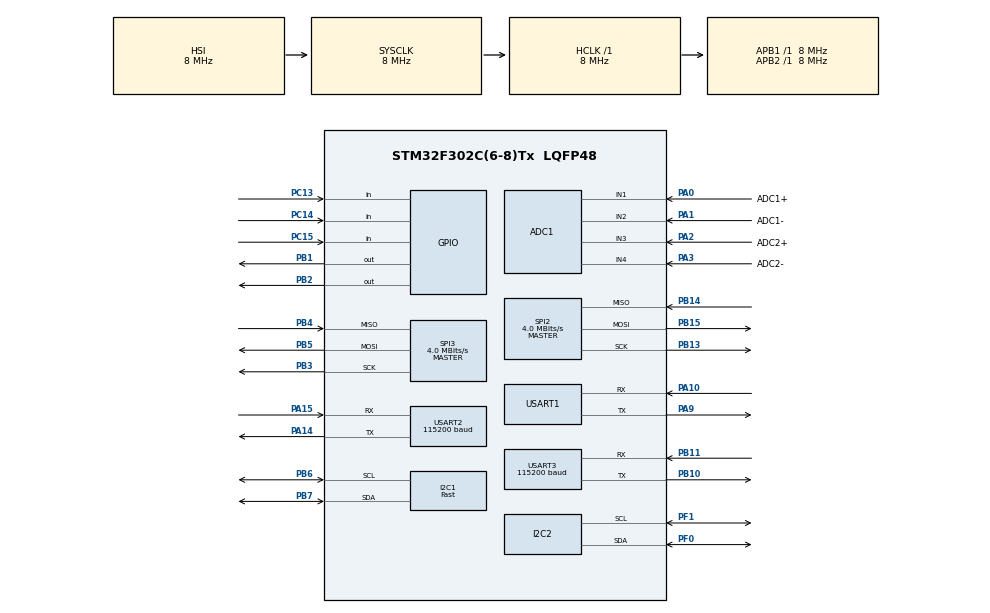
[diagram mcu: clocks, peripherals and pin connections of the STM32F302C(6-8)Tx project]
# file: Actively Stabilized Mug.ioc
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ADC1.Channel-2\#ChannelRegularConversion=ADC_CHANNEL_1
ADC1.NbrOfConversionFlag=1
ADC1.Offset-2\#ChannelRegularConversion=0
ADC1.OffsetNumber-2\#ChannelRegularConversion=ADC_OFFSET_NONE
ADC1.Rank-2\#ChannelRegularConversion=1
ADC1.SamplingTime-2\#ChannelRegularConversion=ADC_SAMPLETIME_1CYCLE_5
ADC1.SingleDiff-2\#ChannelRegularConversion=ADC_DIFFERENTIAL_ENDED
ADC1.SubFamily=STM32F302x8
ADC1.master=1
I2C1.I2C_Speed_Mode=I2C_Fast
I2C1.Timing=0x0000020B
Mcu.Family=STM32F3
Mcu.Name=STM32F302C(6-8)Tx
Mcu.Package=LQFP48
NVIC.PriorityGroup=NVIC_PRIORITYGROUP_4
PA0.GPIO_Label=ADC1+
PA0.Mode=IN1-Differential
PA0.Signal=ADC1_IN1
PA1.GPIO_Label=ADC1-
PA1.Mode=IN1-Differential
PA1.Signal=ADC1_IN2
PA10.Mode=Asynchronous
PA10.Signal=USART1_RX
PA14.Mode=Asynchronous
PA14.Signal=USART2_TX
PA15.Mode=Asynchronous
PA15.Signal=USART2_RX
PA2.GPIO_Label=ADC2+
PA2.Mode=IN3-Differential
PA2.Signal=ADC1_IN3
PA3.GPIO_Label=ADC2-
PA3.Mode=IN3-Differential
PA3.Signal=ADC1_IN4
PA9.Mode=Asynchronous
PA9.Signal=USART1_TX
PB1.GPIO_Speed=GPIO_SPEED_FREQ_HIGH
PB1.Signal=GPIO_Output
PB10.GPIO_PuPd=GPIO_PULLUP
PB10.Mode=Asynchronous
PB10.Signal=USART3_TX
PB11.GPIO_PuPd=GPIO_PULLUP
PB11.Mode=Asynchronous
PB11.Signal=USART3_RX
PB13.Mode=Full_Duplex_Master
PB13.Signal=SPI2_SCK
PB14.Mode=Full_Duplex_Master
PB14.Signal=SPI2_MISO
PB15.Mode=Full_Duplex_Master
PB15.Signal=SPI2_MOSI
PB2.Signal=GPIO_Output
PB3.Mode=Full_Duplex_Master
PB3.Signal=SPI3_SCK
PB4.Mode=Full_Duplex_Master
PB4.Signal=SPI3_MISO
PB5.Mode=Full_Duplex_Master
PB5.Signal=SPI3_MOSI
PB6.Mode=I2C
PB6.Signal=I2C1_SCL
PB7.Mode=I2C
PB7.Signal=I2C1_SDA
PC13.Signal=GPIO_Input
PC14\ -\ OSC32_IN.Signal=GPIO_Input
PC15\ -\ OSC32_OUT.Signal=GPIO_Input
PF0-OSC_IN.Mode=I2C
PF0-OSC_IN.Signal=I2C2_SDA
PF1-OSC_OUT.Mode=I2C
PF1-OSC_OUT.Signal=I2C2_SCL
ProjectManager.HeapSize=0x200
ProjectManager.StackSize=0x400
ProjectManager.TargetToolchain=STM32CubeIDE
RCC.AHBFreq_Value=8000000
RCC.APB1Freq_Value=8000000
RCC.APB1TimFreq_Value=8000000
RCC.APB2Freq_Value=8000000
RCC.CortexFreq_Value=8000000
RCC.HSE_VALUE=8000000
RCC.HSI_VALUE=8000000
RCC.LSE_VALUE=32768
RCC.PLLMUL=RCC_PLL_MUL4
RCC.SYSCLKFreq_VALUE=8000000
RCC.USBFreq_Value=16000000
SPI2.CalculateBaudRate=4.0 MBits/s
SPI2.Direction=SPI_DIRECTION_2LINES
SPI2.Mode=SPI_MODE_MASTER
SPI2.VirtualType=VM_MASTER
SPI3.CalculateBaudRate=4.0 MBits/s
SPI3.Direction=SPI_DIRECTION_2LINES
SPI3.Mode=SPI_MODE_MASTER
SPI3.VirtualType=VM_MASTER
USART1.VirtualMode-Asynchronous=VM_ASYNC
USART2.BaudRate=115200
USART2.VirtualMode-Asynchronous=VM_ASYNC
USART3.BaudRate=115200
USART3.VirtualMode-Asynchronous=VM_ASYNC
board=custom

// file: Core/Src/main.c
/* USER CODE BEGIN Header */
/**
  ******************************************************************************
  * @file           : main.c
  * @brief          : Main program body
  ******************************************************************************
  * @attention
  *
  * Copyright (c) 2022 STMicroelectronics.
  * All rights reserved.
  *
  * This software is licensed under terms that can be found in the LICENSE file
  * in the root directory of this software component.
  * If no LICENSE file comes with this software, it is provided AS-IS.
  *
  ******************************************************************************
  */
/* USER CODE END Header */
#include "main.h"

/* USER CODE BEGIN Includes */
#include "../../MC349/Inc/MC3479.h"
/* USER CODE END Includes */

ADC_HandleTypeDef hadc1;

I2C_HandleTypeDef hi2c1;
I2C_HandleTypeDef hi2c2;

SPI_HandleTypeDef hspi2;
SPI_HandleTypeDef hspi3;

UART_HandleTypeDef huart1;
UART_HandleTypeDef huart2;
UART_HandleTypeDef huart3;

void SystemClock_Config(void);
static void MX_GPIO_Init(void);
static void MX_ADC1_Init(void);
static void MX_I2C1_Init(void);
static void MX_I2C2_Init(void);
static void MX_USART1_UART_Init(void);
static void MX_USART2_UART_Init(void);
static void MX_USART3_UART_Init(void);
static void MX_SPI2_Init(void);
static void MX_SPI3_Init(void);

int main(void)
{

  /* MCU Configuration--------------------------------------------------------*/

  /* Reset of all peripherals, Initializes the Flash interface and the Systick. */
  HAL_Init();

  /* Configure the system clock */
  SystemClock_Config();

  /* Initialize all configured peripherals */
  MX_GPIO_Init();
  MX_ADC1_Init();
  MX_I2C1_Init();
  MX_I2C2_Init();
  MX_USART1_UART_Init();
  MX_USART2_UART_Init();
  MX_USART3_UART_Init();
  MX_SPI2_Init();
  MX_SPI3_Init();

  /* Infinite loop */
  while (1)
  {

  }
}

void SystemClock_Config(void)
{
  RCC_OscInitTypeDef RCC_OscInitStruct = {0};
  RCC_ClkInitTypeDef RCC_ClkInitStruct = {0};
  RCC_PeriphCLKInitTypeDef PeriphClkInit = {0};

  /** Initializes the RCC Oscillators according to the specified parameters
  * in the RCC_OscInitTypeDef structure.
  */
  RCC_OscInitStruct.OscillatorType = RCC_OSCILLATORTYPE_HSI;
  RCC_OscInitStruct.HSIState = RCC_HSI_ON;
  RCC_OscInitStruct.HSICalibrationValue = RCC_HSICALIBRATION_DEFAULT;
  RCC_OscInitStruct.PLL.PLLState = RCC_PLL_ON;
  RCC_OscInitStruct.PLL.PLLSource = RCC_PLLSOURCE_HSI;
  RCC_OscInitStruct.PLL.PLLMUL = RCC_PLL_MUL4;
  if (HAL_RCC_OscConfig(&RCC_OscInitStruct) != HAL_OK)
  {
    Error_Handler();
  }

  /** Initializes the CPU, AHB and APB buses clocks
  */
  RCC_ClkInitStruct.ClockType = RCC_CLOCKTYPE_HCLK|RCC_CLOCKTYPE_SYSCLK
                              |RCC_CLOCKTYPE_PCLK1|RCC_CLOCKTYPE_PCLK2;
  RCC_ClkInitStruct.SYSCLKSource = RCC_SYSCLKSOURCE_HSI;
  RCC_ClkInitStruct.AHBCLKDivider = RCC_SYSCLK_DIV1;
  RCC_ClkInitStruct.APB1CLKDivider = RCC_HCLK_DIV1;
  RCC_ClkInitStruct.APB2CLKDivider = RCC_HCLK_DIV1;

  if (HAL_RCC_ClockConfig(&RCC_ClkInitStruct, FLASH_LATENCY_0) != HAL_OK)
  {
    Error_Handler();
  }
  PeriphClkInit.PeriphClockSelection = RCC_PERIPHCLK_USART1|RCC_PERIPHCLK_I2C1
                              |RCC_PERIPHCLK_I2C2|RCC_PERIPHCLK_ADC1;
  PeriphClkInit.Usart1ClockSelection = RCC_USART1CLKSOURCE_PCLK1;
  PeriphClkInit.I2c1ClockSelection = RCC_I2C1CLKSOURCE_HSI;
  PeriphClkInit.I2c2ClockSelection = RCC_I2C2CLKSOURCE_HSI;
  PeriphClkInit.Adc1ClockSelection = RCC_ADC1PLLCLK_DIV1;

  if (HAL_RCCEx_PeriphCLKConfig(&PeriphClkInit) != HAL_OK)
  {
    Error_Handler();
  }
}

static void MX_ADC1_Init(void)
{

  ADC_ChannelConfTypeDef sConfig = {0};

  /** Common config
  */
  hadc1.Instance = ADC1;
  hadc1.Init.ClockPrescaler = ADC_CLOCK_ASYNC_DIV1;
  hadc1.Init.Resolution = ADC_RESOLUTION_12B;
  hadc1.Init.ScanConvMode = ADC_SCAN_DISABLE;
  hadc1.Init.ContinuousConvMode = DISABLE;
  hadc1.Init.DiscontinuousConvMode = DISABLE;
  hadc1.Init.ExternalTrigConvEdge = ADC_EXTERNALTRIGCONVEDGE_NONE;
  hadc1.Init.ExternalTrigConv = ADC_SOFTWARE_START;
  hadc1.Init.DataAlign = ADC_DATAALIGN_RIGHT;
  hadc1.Init.NbrOfConversion = 1;
  hadc1.Init.DMAContinuousRequests = DISABLE;
  hadc1.Init.EOCSelection = ADC_EOC_SINGLE_CONV;
  hadc1.Init.LowPowerAutoWait = DISABLE;
  hadc1.Init.Overrun = ADC_OVR_DATA_OVERWRITTEN;
  if (HAL_ADC_Init(&hadc1) != HAL_OK)
  {
    Error_Handler();
  }

  /** Configure Regular Channel
  */
  sConfig.Channel = ADC_CHANNEL_1;
  sConfig.Rank = ADC_REGULAR_RANK_1;
  sConfig.SingleDiff = ADC_DIFFERENTIAL_ENDED;
  sConfig.SamplingTime = ADC_SAMPLETIME_1CYCLE_5;
  sConfig.OffsetNumber = ADC_OFFSET_NONE;
  sConfig.Offset = 0;
  if (HAL_ADC_ConfigChannel(&hadc1, &sConfig) != HAL_OK)
  {
    Error_Handler();
  }

}

static void MX_I2C1_Init(void)
{

  hi2c1.Instance = I2C1;
  hi2c1.Init.Timing = 0x0000020B;
  hi2c1.Init.OwnAddress1 = 0;
  hi2c1.Init.AddressingMode = I2C_ADDRESSINGMODE_7BIT;
  hi2c1.Init.DualAddressMode = I2C_DUALADDRESS_DISABLE;
  hi2c1.Init.OwnAddress2 = 0;
  hi2c1.Init.OwnAddress2Masks = I2C_OA2_NOMASK;
  hi2c1.Init.GeneralCallMode = I2C_GENERALCALL_DISABLE;
  hi2c1.Init.NoStretchMode = I2C_NOSTRETCH_DISABLE;
  if (HAL_I2C_Init(&hi2c1) != HAL_OK)
  {
    Error_Handler();
  }

  /** Configure Analogue filter
  */
  if (HAL_I2CEx_ConfigAnalogFilter(&hi2c1, I2C_ANALOGFILTER_ENABLE) != HAL_OK)
  {
    Error_Handler();
  }

  /** Configure Digital filter
  */
  if (HAL_I2CEx_ConfigDigitalFilter(&hi2c1, 0) != HAL_OK)
  {
    Error_Handler();
  }

}

static void MX_I2C2_Init(void)
{

  hi2c2.Instance = I2C2;
  hi2c2.Init.Timing = 0x2000090E;
  hi2c2.Init.OwnAddress1 = 0;
  hi2c2.Init.AddressingMode = I2C_ADDRESSINGMODE_7BIT;
  hi2c2.Init.DualAddressMode = I2C_DUALADDRESS_DISABLE;
  hi2c2.Init.OwnAddress2 = 0;
  hi2c2.Init.OwnAddress2Masks = I2C_OA2_NOMASK;
  hi2c2.Init.GeneralCallMode = I2C_GENERALCALL_DISABLE;
  hi2c2.Init.NoStretchMode = I2C_NOSTRETCH_DISABLE;
  if (HAL_I2C_Init(&hi2c2) != HAL_OK)
  {
    Error_Handler();
  }

  /** Configure Analogue filter
  */
  if (HAL_I2CEx_ConfigAnalogFilter(&hi2c2, I2C_ANALOGFILTER_ENABLE) != HAL_OK)
  {
    Error_Handler();
  }

  /** Configure Digital filter
  */
  if (HAL_I2CEx_ConfigDigitalFilter(&hi2c2, 0) != HAL_OK)
  {
    Error_Handler();
  }

}

static void MX_SPI2_Init(void)
{

  /* SPI2 parameter configuration*/
  hspi2.Instance = SPI2;
  hspi2.Init.Mode = SPI_MODE_MASTER;
  hspi2.Init.Direction = SPI_DIRECTION_2LINES;
  hspi2.Init.DataSize = SPI_DATASIZE_4BIT;
  hspi2.Init.CLKPolarity = SPI_POLARITY_LOW;
  hspi2.Init.CLKPhase = SPI_PHASE_1EDGE;
  hspi2.Init.NSS = SPI_NSS_SOFT;
  hspi2.Init.BaudRatePrescaler = SPI_BAUDRATEPRESCALER_2;
  hspi2.Init.FirstBit = SPI_FIRSTBIT_MSB;
  hspi2.Init.TIMode = SPI_TIMODE_DISABLE;
  hspi2.Init.CRCCalculation = SPI_CRCCALCULATION_DISABLE;
  hspi2.Init.CRCPolynomial = 7;
  hspi2.Init.CRCLength = SPI_CRC_LENGTH_DATASIZE;
  hspi2.Init.NSSPMode = SPI_NSS_PULSE_ENABLE;
  if (HAL_SPI_Init(&hspi2) != HAL_OK)
  {
    Error_Handler();
  }

}

static void MX_SPI3_Init(void)
{

  /* SPI3 parameter configuration*/
  hspi3.Instance = SPI3;
  hspi3.Init.Mode = SPI_MODE_MASTER;
  hspi3.Init.Direction = SPI_DIRECTION_2LINES;
  hspi3.Init.DataSize = SPI_DATASIZE_4BIT;
  hspi3.Init.CLKPolarity = SPI_POLARITY_LOW;
  hspi3.Init.CLKPhase = SPI_PHASE_1EDGE;
  hspi3.Init.NSS = SPI_NSS_SOFT;
  hspi3.Init.BaudRatePrescaler = SPI_BAUDRATEPRESCALER_2;
  hspi3.Init.FirstBit = SPI_FIRSTBIT_MSB;
  hspi3.Init.TIMode = SPI_TIMODE_DISABLE;
  hspi3.Init.CRCCalculation = SPI_CRCCALCULATION_DISABLE;
  hspi3.Init.CRCPolynomial = 7;
  hspi3.Init.CRCLength = SPI_CRC_LENGTH_DATASIZE;
  hspi3.Init.NSSPMode = SPI_NSS_PULSE_ENABLE;
  if (HAL_SPI_Init(&hspi3) != HAL_OK)
  {
    Error_Handler();
  }

}

static void MX_USART1_UART_Init(void)
{

  huart1.Instance = USART1;
  huart1.Init.BaudRate = 38400;
  huart1.Init.WordLength = UART_WORDLENGTH_8B;
  huart1.Init.StopBits = UART_STOPBITS_1;
  huart1.Init.Parity = UART_PARITY_NONE;
  huart1.Init.Mode = UART_MODE_TX_RX;
  huart1.Init.HwFlowCtl = UART_HWCONTROL_NONE;
  huart1.Init.OverSampling = UART_OVERSAMPLING_16;
  huart1.Init.OneBitSampling = UART_ONE_BIT_SAMPLE_DISABLE;
  huart1.AdvancedInit.AdvFeatureInit = UART_ADVFEATURE_NO_INIT;
  if (HAL_UART_Init(&huart1) != HAL_OK)
  {
    Error_Handler();
  }

}

static void MX_USART2_UART_Init(void)
{

  huart2.Instance = USART2;
  huart2.Init.BaudRate = 115200;
  huart2.Init.WordLength = UART_WORDLENGTH_8B;
  huart2.Init.StopBits = UART_STOPBITS_1;
  huart2.Init.Parity = UART_PARITY_NONE;
  huart2.Init.Mode = UART_MODE_TX_RX;
  huart2.Init.HwFlowCtl = UART_HWCONTROL_NONE;
  huart2.Init.OverSampling = UART_OVERSAMPLING_16;
  huart2.Init.OneBitSampling = UART_ONE_BIT_SAMPLE_DISABLE;
  huart2.AdvancedInit.AdvFeatureInit = UART_ADVFEATURE_NO_INIT;
  if (HAL_UART_Init(&huart2) != HAL_OK)
  {
    Error_Handler();
  }

}

static void MX_USART3_UART_Init(void)
{

  huart3.Instance = USART3;
  huart3.Init.BaudRate = 115200;
  huart3.Init.WordLength = UART_WORDLENGTH_8B;
  huart3.Init.StopBits = UART_STOPBITS_1;
  huart3.Init.Parity = UART_PARITY_NONE;
  huart3.Init.Mode = UART_MODE_TX_RX;
  huart3.Init.HwFlowCtl = UART_HWCONTROL_NONE;
  huart3.Init.OverSampling = UART_OVERSAMPLING_16;
  huart3.Init.OneBitSampling = UART_ONE_BIT_SAMPLE_DISABLE;
  huart3.AdvancedInit.AdvFeatureInit = UART_ADVFEATURE_NO_INIT;
  if (HAL_UART_Init(&huart3) != HAL_OK)
  {
    Error_Handler();
  }

}

static void MX_GPIO_Init(void)
{
  GPIO_InitTypeDef GPIO_InitStruct = {0};

  /* GPIO Ports Clock Enable */
  __HAL_RCC_GPIOC_CLK_ENABLE();
  __HAL_RCC_GPIOF_CLK_ENABLE();
  __HAL_RCC_GPIOA_CLK_ENABLE();
  __HAL_RCC_GPIOB_CLK_ENABLE();

  /*Configure GPIO pin Output Level */
  HAL_GPIO_WritePin(GPIOB, GPIO_PIN_1|GPIO_PIN_2, GPIO_PIN_RESET);

  /*Configure GPIO pins : PC13 PC14 PC15 */
  GPIO_InitStruct.Pin = GPIO_PIN_13|GPIO_PIN_14|GPIO_PIN_15;
  GPIO_InitStruct.Mode = GPIO_MODE_INPUT;
  GPIO_InitStruct.Pull = GPIO_NOPULL;
  HAL_GPIO_Init(GPIOC, &GPIO_InitStruct);

  /*Configure GPIO pin : PB1 */
  GPIO_InitStruct.Pin = GPIO_PIN_1;
  GPIO_InitStruct.Mode = GPIO_MODE_OUTPUT_PP;
  GPIO_InitStruct.Pull = GPIO_NOPULL;
  GPIO_InitStruct.Speed = GPIO_SPEED_FREQ_HIGH;
  HAL_GPIO_Init(GPIOB, &GPIO_InitStruct);

  /*Configure GPIO pin : PB2 */
  GPIO_InitStruct.Pin = GPIO_PIN_2;
  GPIO_InitStruct.Mode = GPIO_MODE_OUTPUT_PP;
  GPIO_InitStruct.Pull = GPIO_NOPULL;
  GPIO_InitStruct.Speed = GPIO_SPEED_FREQ_LOW;
  HAL_GPIO_Init(GPIOB, &GPIO_InitStruct);

}

void Error_Handler(void)
{
  __disable_irq();
  while (1)
  {
  }
}
